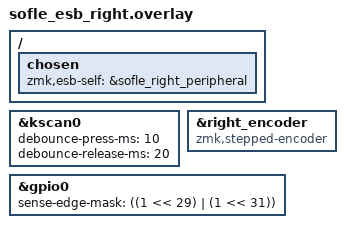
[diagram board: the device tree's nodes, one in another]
#include "sofle_esb.dtsi"

/ {
    chosen {
        zmk,esb-self = &sofle_right_peripheral;
    };
};

&kscan0 {
    debounce-press-ms = <10>;
    debounce-release-ms = <20>;
};

&right_encoder {
    compatible = "zmk,stepped-encoder";
};

&gpio0 {
    sense-edge-mask = <((1 << 29) | (1 << 31))>;
};
